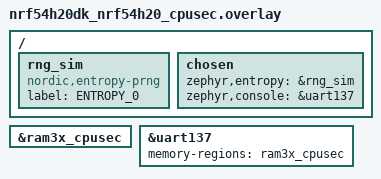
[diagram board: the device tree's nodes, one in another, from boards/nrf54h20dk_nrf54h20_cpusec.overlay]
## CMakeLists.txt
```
#
# Copyright (c) 2022 Nordic Semiconductor ASA
#
# SPDX-License-Identifier: LicenseRef-Nordic-5-Clause
#

cmake_minimum_required(VERSION 3.20.0)

find_package(Zephyr REQUIRED HINTS $ENV{ZEPHYR_BASE})

project(integration_test_fetch_integrated_payload)
include(../cmake/test_template.cmake)
```

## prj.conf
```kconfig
#
# Copyright (c) 2022 Nordic Semiconductor ASA
#
# SPDX-License-Identifier: LicenseRef-Nordic-5-Clause
#

CONFIG_ZTEST=y
CONFIG_ZTEST_NEW_API=y

CONFIG_SUIT=y
CONFIG_SUIT_CRYPTO=y
CONFIG_SUIT_PROCESSOR=y
CONFIG_SUIT_PLATFORM=y
CONFIG_SUIT_COMPONENT_RAMBUF=y
CONFIG_SUIT_LOG_LEVEL_DBG=y

CONFIG_SUIT_UTILS=y
CONFIG_SUIT_MEMPTR_STORAGE=y

CONFIG_ZCBOR=y
CONFIG_ZCBOR_CANONICAL=y
```

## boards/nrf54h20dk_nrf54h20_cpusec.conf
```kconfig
#
# Copyright (c) 2022 Nordic Semiconductor ASA
#
# SPDX-License-Identifier: LicenseRef-Nordic-5-Clause
#

CONFIG_NULL_POINTER_EXCEPTION_DETECTION_NONE=y
CONFIG_SERIAL=y
CONFIG_CONSOLE=y
CONFIG_UART_CONSOLE=y

# This test does not set 'IS_SECURE_DOMAIN_FW'. Hence, we need to enable the
# bare minimum configurations for running on bare metal Secure Domain.
CONFIG_SECDOM_MINIMUM_TEST_CONFIGS=y

# Logging and printk is using standard UART.
CONFIG_LOG_MODE_DEFERRED=y
CONFIG_LOG_BACKEND_UART=y
CONFIG_LOG_PRINTK=y
CONFIG_LOG_BUFFER_SIZE=8192
```

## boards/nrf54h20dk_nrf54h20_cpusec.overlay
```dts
/*
 * Copyright (c) 2022 Nordic Semiconductor ASA
 *
 * SPDX-License-Identifier: LicenseRef-Nordic-5-Clause
 */

/ {
	rng_sim: rng_sim {
		status = "okay";
		compatible = "nordic,entropy-prng";
		label = "ENTROPY_0";
	};

	chosen {
		zephyr,entropy = &rng_sim;
		zephyr,console = &uart137;
	};
};

&ram3x_cpusec {
	status = "okay";
};

&uart137 {
	status = "okay";
	memory-regions = <&ram3x_cpusec>;
};
```

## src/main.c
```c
/*
 * Copyright (c) 2022 Nordic Semiconductor ASA
 *
 * SPDX-License-Identifier: LicenseRef-Nordic-5-Clause
 */

#include <zephyr/ztest.h>
#include <stdint.h>
#include <psa/crypto.h>

#include <suit.h>
#include <suit_platform.h>

/* The SUIT envelope is defined inside the board-specific manfest_*.c file. */
extern uint8_t manifest_buf[];
extern const size_t manifest_len;

static const uint8_t public_key[] = {
	0x04, /* POINT_CONVERSION_UNCOMPRESSED */
	0xed, 0xd0, 0x9e, 0xa5, 0xec, 0xe4, 0xed, 0xbe, 0x6c, 0x08, 0xe7, 0x47, 0x09,
	0x55, 0x9a, 0x38, 0x29, 0xc5, 0x31, 0x33, 0x22, 0x7b, 0xf4, 0xf0, 0x11, 0x6e,
	0x8c, 0x05, 0x2d, 0x02, 0x0e, 0x0e, 0xc3, 0xe0, 0xd8, 0x37, 0xf4, 0xc2, 0x6f,
	0xc1, 0x28, 0x80, 0x2f, 0x45, 0x38, 0x1a, 0x23, 0x2b, 0x6d, 0xd5, 0xda, 0x28,
	0x60, 0x00, 0x5d, 0xab, 0xe2, 0xa0, 0x83, 0xdb, 0xef, 0x38, 0x55, 0x13};
psa_key_id_t public_key_id;

static int load_keys(void)
{
	psa_status_t status = PSA_ERROR_GENERIC_ERROR;

	/* Initialize PSA Crypto */
	status = psa_crypto_init();
	if (status != PSA_SUCCESS) {
		printk("Failed to initialize PSA Crypto\n");
		return SUIT_ERR_CRASH;
	}

	/* Add keys */
	psa_key_attributes_t key_attributes = PSA_KEY_ATTRIBUTES_INIT;

	psa_set_key_usage_flags(&key_attributes, PSA_KEY_USAGE_VERIFY_HASH);
	psa_set_key_algorithm(&key_attributes, PSA_ALG_ECDSA(PSA_ALG_SHA_256));
	psa_set_key_type(&key_attributes, PSA_KEY_TYPE_ECC_PUBLIC_KEY(PSA_ECC_FAMILY_SECP_R1));

	status = psa_import_key(&key_attributes, public_key, sizeof(public_key), &public_key_id);
	if (status != PSA_SUCCESS) {
		printk("Failed to add public key\n");
		return SUIT_ERR_CRASH;
	}
	printk("Loaded key ID: 0x%x\n", public_key_id);

	return SUIT_SUCCESS;
}

static int destroy_keys(void)
{
	/* Remove public key from the driver */
	int ret = psa_destroy_key(public_key_id);

	return ret;
}

static void *test_suit_setup(void)
{
	int err = load_keys();
	zassert_equal(err, 0, "Unable to initialize crypto backend\n");

	return NULL;
}

static void test_suit_teardown(void *f)
{
	int err = destroy_keys();
	zassert_equal(err, 0, "Unable to uninitialize crypto backend\n");
}

ZTEST_SUITE(fetch_integrated_payoad_tests, NULL, test_suit_setup, NULL, NULL, test_suit_teardown);

/** @brief Authenticate, validate and execute all command sequences from the sample SUIT envelope.
 *
 * @details The main purpose of this test is to give an entry point for SUIT processor platform
 * implementation. If the platform design requires it, please update the envelope payload, defined
 * at the beginning of this file.
 */
ZTEST(fetch_integrated_payoad_tests, test_suit_process)
{
	int err = SUIT_SUCCESS;

	err = suit_processor_init();
	zassert_equal(err, 0, "Unable to initialise SUIT processor (err: %d)", err);

	err = suit_process_sequence(manifest_buf, manifest_len, SUIT_SEQ_PARSE);
	zassert_equal(err, 0, "Parsing SUIT envelope failed (err: %d)", err);

	for (enum suit_command_sequence i = SUIT_SEQ_PARSE + 1; (i < SUIT_SEQ_MAX) && (err == 0);
	     i++) {
		err = suit_process_sequence(manifest_buf, manifest_len, i);
		if (err == SUIT_ERR_UNAVAILABLE_COMMAND_SEQ) {
			err = 0;
		}
		zassert_equal(err, 0, "Processing SUIT sequence %d failed with error %i", i, err);
	}
}
```

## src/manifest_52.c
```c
/*
 * Copyright (c) 2023 Nordic Semiconductor ASA
 *
 * SPDX-License-Identifier: LicenseRef-Nordic-5-Clause
 */
#if defined(CONFIG_SOC_NRF52840) || defined(CONFIG_BOARD_NATIVE_POSIX)
#include <suit_types.h>

/** @brief SUIT envelope generated using the manifest/manifest_52.yaml input file.
 *
 * @details This envelope contains 256-byte random numbers attached as an integrated
 *          payload and fetched directly into the memory-mapped region during install step.
 *          The envelope has been signed using the manifest/key_private.pem key.
 *
 * @note Please use the manifest_common/regenerate.sh script for regenerating payloads.
 */
uint8_t manifest_buf[] = {
	0xD8, 0x6B, 0xA4, 0x02, 0x58, 0x7A, 0x82, 0x58, 0x24, 0x82, 0x2F, 0x58, 0x20, 0xC2, 0xEE,
	0x56, 0x00, 0xE9, 0x08, 0x9C, 0xCD, 0x62, 0xE4, 0xD9, 0x36, 0x00, 0xE2, 0x42, 0xCD, 0xC4,
	0x9F, 0xE4, 0x0F, 0xCC, 0x01, 0x60, 0x7F, 0x4B, 0x40, 0xE3, 0xB4, 0x28, 0x45, 0x53, 0xA8,
	0x58, 0x51, 0xD2, 0x84, 0x4A, 0xA2, 0x01, 0x26, 0x04, 0x45, 0x1A, 0x7F, 0xFF, 0xFF, 0xE0,
	0xA0, 0xF6, 0x58, 0x40, 0x03, 0xCE, 0x55, 0x83, 0x7B, 0x69, 0x63, 0x46, 0x70, 0x84, 0x3C,
	0xE5, 0x42, 0xD2, 0x07, 0x42, 0x7B, 0xED, 0x35, 0x3D, 0x2E, 0xEC, 0x26, 0xDA, 0xC7, 0x1A,
	0xD4, 0xE0, 0x8A, 0xBD, 0x9E, 0xD7, 0x55, 0xD1, 0xEB, 0x2F, 0x33, 0xC3, 0x61, 0xD4, 0x79,
	0xC0, 0x53, 0x8A, 0x2C, 0x68, 0xC5, 0x43, 0xCA, 0x29, 0xC4, 0xB6, 0xB3, 0xDA, 0xFC, 0xBB,
	0xA4, 0x0D, 0x76, 0xB4, 0x2D, 0xD1, 0x8F, 0xC1, 0x03, 0x58, 0xD9, 0xA8, 0x01, 0x01, 0x02,
	0x01, 0x03, 0x58, 0x6E, 0xA2, 0x02, 0x81, 0x84, 0x44, 0x63, 0x4D, 0x45, 0x4D, 0x41, 0x00,
	0x45, 0x1A, 0x00, 0x08, 0x00, 0x00, 0x43, 0x19, 0x10, 0x00, 0x04, 0x58, 0x56, 0x86, 0x14,
	0xA4, 0x01, 0x50, 0x76, 0x17, 0xDA, 0xA5, 0x71, 0xFD, 0x5A, 0x85, 0x8F, 0x94, 0xE2, 0x8D,
	0x73, 0x5C, 0xE9, 0xF4, 0x02, 0x50, 0x56, 0xDC, 0x9A, 0x14, 0x28, 0xD8, 0x52, 0xD3, 0xBD,
	0x62, 0xE7, 0x7A, 0x08, 0xBC, 0x8B, 0x91, 0x03, 0x58, 0x24, 0x82, 0x2F, 0x58, 0x20, 0x5F,
	0xC3, 0x54, 0xBF, 0x8E, 0x8C, 0x50, 0xFB, 0x4F, 0xBC, 0x2C, 0xFA, 0xEB, 0x04, 0x53, 0x41,
	0xC9, 0x80, 0x6D, 0xEA, 0xBD, 0xCB, 0x41, 0x54, 0xFB, 0x79, 0xCC, 0xA4, 0xF0, 0xC9, 0x8C,
	0x12, 0x0E, 0x19, 0x01, 0x00, 0x01, 0x0F, 0x02, 0x0F, 0x07, 0x43, 0x82, 0x03, 0x0F, 0x09,
	0x43, 0x82, 0x17, 0x02, 0x11, 0x52, 0x86, 0x14, 0xA1, 0x15, 0x69, 0x23, 0x66, 0x69, 0x6C,
	0x65, 0x2E, 0x62, 0x69, 0x6E, 0x15, 0x02, 0x03, 0x0F, 0x17, 0x82, 0x2F, 0x58, 0x20, 0x60,
	0xA8, 0x0D, 0xFD, 0xD4, 0xBF, 0x59, 0x42, 0x7E, 0x92, 0x7C, 0xA6, 0x93, 0x58, 0x63, 0xE1,
	0xF6, 0x04, 0x9A, 0x50, 0xE5, 0x0E, 0xB6, 0xF5, 0x3B, 0x81, 0x67, 0x29, 0x53, 0x14, 0xA7,
	0x9A, 0x05, 0x82, 0x4C, 0x6B, 0x49, 0x4E, 0x53, 0x54, 0x4C, 0x44, 0x5F, 0x4D, 0x46, 0x53,
	0x54, 0x50, 0x56, 0xDC, 0x9A, 0x14, 0x28, 0xD8, 0x52, 0xD3, 0xBD, 0x62, 0xE7, 0x7A, 0x08,
	0xBC, 0x8B, 0x91, 0x17, 0x58, 0x84, 0xA1, 0x84, 0x44, 0x63, 0x4D, 0x45, 0x4D, 0x41, 0x00,
	0x45, 0x1A, 0x00, 0x08, 0x00, 0x00, 0x43, 0x19, 0x10, 0x00, 0xA6, 0x01, 0x78, 0x18, 0x4E,
	0x6F, 0x72, 0x64, 0x69, 0x63, 0x20, 0x53, 0x65, 0x6D, 0x69, 0x63, 0x6F, 0x6E, 0x64, 0x75,
	0x63, 0x74, 0x6F, 0x72, 0x20, 0x41, 0x53, 0x41, 0x02, 0x65, 0x70, 0x6F, 0x73, 0x69, 0x78,
	0x03, 0x6E, 0x6E, 0x6F, 0x72, 0x64, 0x69, 0x63, 0x73, 0x65, 0x6D, 0x69, 0x2E, 0x63, 0x6F,
	0x6D, 0x04, 0x75, 0x54, 0x68, 0x65, 0x20, 0x50, 0x4F, 0x53, 0x49, 0x58, 0x20, 0x61, 0x70,
	0x70, 0x6C, 0x69, 0x63, 0x61, 0x74, 0x69, 0x6F, 0x6E, 0x05, 0x78, 0x1C, 0x53, 0x61, 0x6D,
	0x70, 0x6C, 0x65, 0x20, 0x61, 0x70, 0x70, 0x6C, 0x69, 0x63, 0x61, 0x74, 0x69, 0x6F, 0x6E,
	0x20, 0x66, 0x6F, 0x72, 0x20, 0x50, 0x4F, 0x53, 0x49, 0x58, 0x06, 0x66, 0x76, 0x31, 0x2E,
	0x30, 0x2E, 0x30, 0x69, 0x23, 0x66, 0x69, 0x6C, 0x65, 0x2E, 0x62, 0x69, 0x6E, 0x59, 0x01,
	0x00, 0xC7, 0x9C, 0xAB, 0x9D, 0xE8, 0x33, 0x7F, 0x30, 0x14, 0xEB, 0xAC, 0x02, 0xAF, 0x26,
	0x01, 0x5E, 0x80, 0x6D, 0x88, 0xA1, 0xDB, 0x11, 0xA7, 0x31, 0xDF, 0xA6, 0xEC, 0xCB, 0x9B,
	0x48, 0x0D, 0xC8, 0x34, 0x40, 0x6D, 0x30, 0x86, 0x7D, 0xE8, 0x1B, 0xEC, 0x3C, 0xF5, 0x40,
	0xD0, 0x48, 0x18, 0x82, 0x11, 0x9D, 0x7C, 0x3F, 0x6C, 0xE5, 0x8F, 0xF1, 0xD3, 0x5D, 0xE1,
	0x51, 0xF7, 0x6A, 0x0F, 0xAF, 0x0B, 0xBD, 0x4C, 0x5F, 0xA5, 0x34, 0x1A, 0x66, 0xDB, 0x22,
	0xEC, 0x63, 0xED, 0x4B, 0xAB, 0xC7, 0xC8, 0xF7, 0x59, 0xD8, 0xD6, 0x9E, 0xEC, 0x71, 0x1B,
	0x24, 0x20, 0xB9, 0xAE, 0xE1, 0x3B, 0xFC, 0xAE, 0xB8, 0x77, 0xAC, 0xA4, 0x57, 0x34, 0x97,
	0x84, 0x4F, 0x58, 0xD5, 0x68, 0x08, 0x6F, 0xE3, 0x9C, 0x7E, 0x1B, 0xD7, 0x38, 0x22, 0x98,
	0x48, 0xF8, 0x7A, 0x67, 0xB2, 0xD9, 0xAC, 0xC5, 0x34, 0xC1, 0x27, 0x82, 0x8E, 0x42, 0x79,
	0x84, 0x21, 0x37, 0x4C, 0x41, 0x4A, 0x0F, 0xE2, 0x7F, 0xA0, 0x6A, 0x19, 0x13, 0x3D, 0x52,
	0x22, 0x7F, 0xD6, 0x2F, 0x71, 0x12, 0x76, 0xAB, 0x25, 0x9C, 0xFC, 0x67, 0x08, 0x03, 0x7C,
	0xDB, 0x18, 0xE6, 0x45, 0xF8, 0x99, 0xC2, 0x9E, 0x2C, 0xE3, 0x9B, 0x25, 0xA9, 0x7B, 0x09,
	0xFF, 0x00, 0x57, 0x26, 0x08, 0x0A, 0x11, 0x42, 0xCF, 0x82, 0xA2, 0x6B, 0x2A, 0x99, 0xF9,
	0x71, 0x9D, 0x14, 0x19, 0x5C, 0x5C, 0x78, 0x31, 0x60, 0x42, 0x4A, 0x18, 0x1F, 0xEC, 0x78,
	0x6A, 0x9A, 0x7C, 0x4F, 0xCF, 0xE8, 0x5A, 0x29, 0x65, 0xCD, 0x01, 0x3B, 0x6D, 0x53, 0xBB,
	0xC6, 0xDB, 0xDA, 0xD5, 0x8F, 0xF7, 0xF4, 0xD9, 0xB9, 0x0A, 0x03, 0x4B, 0xFF, 0x33, 0xAB,
	0x3B, 0xC5, 0xAF, 0xD0, 0xB8, 0x2C, 0x0F, 0x6A, 0xA9, 0x11, 0xB0, 0xE8, 0x57, 0x8C, 0x92,
	0x53, 0x81};

const size_t manifest_len = sizeof(manifest_buf);
#endif /* CONFIG_SOC_NRF52840 || CONFIG_BOARD_NATIVE_POSIX */
```

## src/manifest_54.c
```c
/*
 * Copyright (c) 2023 Nordic Semiconductor ASA
 *
 * SPDX-License-Identifier: LicenseRef-Nordic-5-Clause
 */
#if defined(CONFIG_SOC_NRF54H20)
#include <suit_types.h>

/** @brief SUIT envelope generated using the manifest/manifest_54.yaml input file.
 *
 * @details This envelope contains 256-byte random numbers attached as an integrated
 *          payload and fetched directly into the memory-mapped region during install step.
 *          The envelope has been signed using the manifest/key_private.pem key.
 *
 * @note Please use the manifest_common/regenerate.sh script for regenerating payloads.
 */
uint8_t manifest_buf[] = {
	0xD8, 0x6B, 0xA4, 0x02, 0x58, 0x7A, 0x82, 0x58, 0x24, 0x82, 0x2F, 0x58, 0x20, 0x26, 0x04,
	0x04, 0xCF, 0x3A, 0xA5, 0x6E, 0xBA, 0x4D, 0xA9, 0xD5, 0xBE, 0xE4, 0x6D, 0x27, 0x33, 0xF3,
	0xD5, 0x4A, 0xD5, 0xE6, 0x72, 0x1E, 0x46, 0xEE, 0x58, 0x93, 0xB6, 0xDC, 0x4D, 0x2C, 0x93,
	0x58, 0x51, 0xD2, 0x84, 0x4A, 0xA2, 0x01, 0x26, 0x04, 0x45, 0x1A, 0x7F, 0xFF, 0xFF, 0xE0,
	0xA0, 0xF6, 0x58, 0x40, 0xCE, 0x6B, 0x73, 0xDA, 0xCE, 0x61, 0xCC, 0x40, 0x14, 0xFE, 0x8B,
	0x87, 0x8A, 0x33, 0xA9, 0x35, 0xCA, 0x1C, 0xB4, 0x57, 0x28, 0xAE, 0x5E, 0x4A, 0xAC, 0x1E,
	0x64, 0x49, 0x68, 0xC1, 0x55, 0x3B, 0x8C, 0xD0, 0x49, 0x84, 0x4F, 0x5C, 0x97, 0x31, 0x2B,
	0x18, 0xBB, 0xEB, 0xB8, 0xB4, 0x61, 0x5B, 0x62, 0xAE, 0x1E, 0xBA, 0xEB, 0x27, 0xB4, 0x87,
	0x74, 0xB9, 0x97, 0x12, 0x05, 0xC5, 0x2D, 0x40, 0x03, 0x58, 0xDB, 0xA8, 0x01, 0x01, 0x02,
	0x01, 0x03, 0x58, 0x70, 0xA2, 0x02, 0x81, 0x84, 0x44, 0x63, 0x4D, 0x45, 0x4D, 0x41, 0x02,
	0x45, 0x1A, 0x0E, 0x0A, 0xA0, 0x00, 0x45, 0x1A, 0x00, 0x07, 0xF8, 0x00, 0x04, 0x58, 0x56,
	0x86, 0x14, 0xA4, 0x01, 0x50, 0x76, 0x17, 0xDA, 0xA5, 0x71, 0xFD, 0x5A, 0x85, 0x8F, 0x94,
	0xE2, 0x8D, 0x73, 0x5C, 0xE9, 0xF4, 0x02, 0x50, 0x08, 0xC1, 0xB5, 0x99, 0x55, 0xE8, 0x5F,
	0xBC, 0x9E, 0x76, 0x7B, 0xC2, 0x9C, 0xE1, 0xB0, 0x4D, 0x03, 0x58, 0x24, 0x82, 0x2F, 0x58,
	0x20, 0x5F, 0xC3, 0x54, 0xBF, 0x8E, 0x8C, 0x50, 0xFB, 0x4F, 0xBC, 0x2C, 0xFA, 0xEB, 0x04,
	0x53, 0x41, 0xC9, 0x80, 0x6D, 0xEA, 0xBD, 0xCB, 0x41, 0x54, 0xFB, 0x79, 0xCC, 0xA4, 0xF0,
	0xC9, 0x8C, 0x12, 0x0E, 0x19, 0x01, 0x00, 0x01, 0x0F, 0x02, 0x0F, 0x07, 0x43, 0x82, 0x03,
	0x0F, 0x09, 0x43, 0x82, 0x17, 0x02, 0x11, 0x52, 0x86, 0x14, 0xA1, 0x15, 0x69, 0x23, 0x66,
	0x69, 0x6C, 0x65, 0x2E, 0x62, 0x69, 0x6E, 0x15, 0x02, 0x03, 0x0F, 0x17, 0x82, 0x2F, 0x58,
	0x20, 0xD5, 0x91, 0xFC, 0x52, 0x92, 0x3A, 0x98, 0x8F, 0x6C, 0x59, 0x25, 0x62, 0x4E, 0xE5,
	0x27, 0x56, 0xA5, 0x90, 0x5B, 0x6C, 0xC4, 0x6C, 0x4B, 0x6A, 0xF6, 0xBA, 0x68, 0xD5, 0x83,
	0x53, 0xD2, 0x59, 0x05, 0x82, 0x4C, 0x6B, 0x49, 0x4E, 0x53, 0x54, 0x4C, 0x44, 0x5F, 0x4D,
	0x46, 0x53, 0x54, 0x50, 0x08, 0xC1, 0xB5, 0x99, 0x55, 0xE8, 0x5F, 0xBC, 0x9E, 0x76, 0x7B,
	0xC2, 0x9C, 0xE1, 0xB0, 0x4D, 0x17, 0x58, 0x97, 0xA1, 0x84, 0x44, 0x63, 0x4D, 0x45, 0x4D,
	0x41, 0x02, 0x45, 0x1A, 0x0E, 0x0A, 0xA0, 0x00, 0x45, 0x1A, 0x00, 0x07, 0xF8, 0x00, 0xA6,
	0x01, 0x78, 0x18, 0x4E, 0x6F, 0x72, 0x64, 0x69, 0x63, 0x20, 0x53, 0x65, 0x6D, 0x69, 0x63,
	0x6F, 0x6E, 0x64, 0x75, 0x63, 0x74, 0x6F, 0x72, 0x20, 0x41, 0x53, 0x41, 0x02, 0x6F, 0x6E,
	0x52, 0x46, 0x35, 0x34, 0x48, 0x32, 0x30, 0x5F, 0x63, 0x70, 0x75, 0x61, 0x70, 0x70, 0x03,
	0x6E, 0x6E, 0x6F, 0x72, 0x64, 0x69, 0x63, 0x73, 0x65, 0x6D, 0x69, 0x2E, 0x63, 0x6F, 0x6D,
	0x04, 0x78, 0x1D, 0x54, 0x68, 0x65, 0x20, 0x6E, 0x52, 0x46, 0x35, 0x34, 0x48, 0x32, 0x30,
	0x20, 0x61, 0x70, 0x70, 0x6C, 0x69, 0x63, 0x61, 0x74, 0x69, 0x6F, 0x6E, 0x20, 0x63, 0x6F,
	0x72, 0x65, 0x05, 0x78, 0x1A, 0x53, 0x61, 0x6D, 0x70, 0x6C, 0x65, 0x20, 0x61, 0x70, 0x70,
	0x6C, 0x69, 0x63, 0x61, 0x74, 0x69, 0x6F, 0x6E, 0x20, 0x63, 0x6F, 0x72, 0x65, 0x20, 0x46,
	0x57, 0x06, 0x66, 0x76, 0x31, 0x2E, 0x30, 0x2E, 0x30, 0x69, 0x23, 0x66, 0x69, 0x6C, 0x65,
	0x2E, 0x62, 0x69, 0x6E, 0x59, 0x01, 0x00, 0xC7, 0x9C, 0xAB, 0x9D, 0xE8, 0x33, 0x7F, 0x30,
	0x14, 0xEB, 0xAC, 0x02, 0xAF, 0x26, 0x01, 0x5E, 0x80, 0x6D, 0x88, 0xA1, 0xDB, 0x11, 0xA7,
	0x31, 0xDF, 0xA6, 0xEC, 0xCB, 0x9B, 0x48, 0x0D, 0xC8, 0x34, 0x40, 0x6D, 0x30, 0x86, 0x7D,
	0xE8, 0x1B, 0xEC, 0x3C, 0xF5, 0x40, 0xD0, 0x48, 0x18, 0x82, 0x11, 0x9D, 0x7C, 0x3F, 0x6C,
	0xE5, 0x8F, 0xF1, 0xD3, 0x5D, 0xE1, 0x51, 0xF7, 0x6A, 0x0F, 0xAF, 0x0B, 0xBD, 0x4C, 0x5F,
	0xA5, 0x34, 0x1A, 0x66, 0xDB, 0x22, 0xEC, 0x63, 0xED, 0x4B, 0xAB, 0xC7, 0xC8, 0xF7, 0x59,
	0xD8, 0xD6, 0x9E, 0xEC, 0x71, 0x1B, 0x24, 0x20, 0xB9, 0xAE, 0xE1, 0x3B, 0xFC, 0xAE, 0xB8,
	0x77, 0xAC, 0xA4, 0x57, 0x34, 0x97, 0x84, 0x4F, 0x58, 0xD5, 0x68, 0x08, 0x6F, 0xE3, 0x9C,
	0x7E, 0x1B, 0xD7, 0x38, 0x22, 0x98, 0x48, 0xF8, 0x7A, 0x67, 0xB2, 0xD9, 0xAC, 0xC5, 0x34,
	0xC1, 0x27, 0x82, 0x8E, 0x42, 0x79, 0x84, 0x21, 0x37, 0x4C, 0x41, 0x4A, 0x0F, 0xE2, 0x7F,
	0xA0, 0x6A, 0x19, 0x13, 0x3D, 0x52, 0x22, 0x7F, 0xD6, 0x2F, 0x71, 0x12, 0x76, 0xAB, 0x25,
	0x9C, 0xFC, 0x67, 0x08, 0x03, 0x7C, 0xDB, 0x18, 0xE6, 0x45, 0xF8, 0x99, 0xC2, 0x9E, 0x2C,
	0xE3, 0x9B, 0x25, 0xA9, 0x7B, 0x09, 0xFF, 0x00, 0x57, 0x26, 0x08, 0x0A, 0x11, 0x42, 0xCF,
	0x82, 0xA2, 0x6B, 0x2A, 0x99, 0xF9, 0x71, 0x9D, 0x14, 0x19, 0x5C, 0x5C, 0x78, 0x31, 0x60,
	0x42, 0x4A, 0x18, 0x1F, 0xEC, 0x78, 0x6A, 0x9A, 0x7C, 0x4F, 0xCF, 0xE8, 0x5A, 0x29, 0x65,
	0xCD, 0x01, 0x3B, 0x6D, 0x53, 0xBB, 0xC6, 0xDB, 0xDA, 0xD5, 0x8F, 0xF7, 0xF4, 0xD9, 0xB9,
	0x0A, 0x03, 0x4B, 0xFF, 0x33, 0xAB, 0x3B, 0xC5, 0xAF, 0xD0, 0xB8, 0x2C, 0x0F, 0x6A, 0xA9,
	0x11, 0xB0, 0xE8, 0x57, 0x8C, 0x92, 0x53, 0x81};

const size_t manifest_len = sizeof(manifest_buf);
#endif /* CONFIG_SOC_NRF54H20 */
```
